AUTOSAR XML (schema 00044)
package /E40_Platform_System_SystemPackage/Components
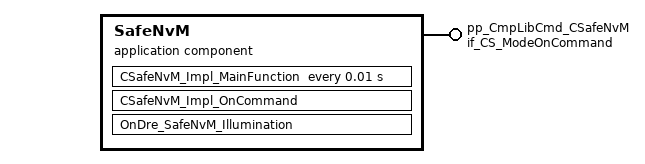
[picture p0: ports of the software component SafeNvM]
  application sw component type SafeNvM
    provide port pp_CmpLibCmd_CSafeNvM: server-com-spec{operation=Impl_OnCommand, queue-length=1}, provided-interface=if_CS_ModeOnCommand
    11 x provide/require port, all with nv-provide-com-spec=Value, nv-require-com-spec=Value:
      BsConst_Derating_Backlight_Disable: provided-required-interface=BsConst_Derating_Backlight_Disable
      BsConst_Temperature_Sensor_Conv: provided-required-interface=BsConst_Temperature_Sensor_Conv
      BsConst_Lookup_Curve_HotSpot_Coef_X: provided-required-interface=BsConst_Lookup_Curve_HotSpot_Coef_X
      BsConst_Display_Illum_Max_Level_Safe: provided-required-interface=BsConst_Display_Illum_Max_Level
      BsConst_Temp_Threshold_Hysteresis_Derating: provided-required-interface=BsConst_Temp_Threshold_Hysteresis_Derating
      BsConst_PWM_boost_bypass_duty: provided-required-interface=BsConst_PWM_boost_bypass_duty
      BsConst_BsConst_Illumination_ReservedByte: provided-required-interface=BsConst_BsConst_Illumination_ReservedByte
      BsConst_Lookup_Curve_HotSpot_Coef_Y: provided-required-interface=BsConst_Lookup_Curve_HotSpot_Coef_Y
      BsConst_Compensation_Line_Shift_b: provided-required-interface=BsConst_Compensation_Line_Shift_b
      BsConst_PCB_Temperature_Sensor_Conv: provided-required-interface=BsConst_PCB_Temperature_Sensor_Conv
      BsConst_Compensation_Line_Slope_m: provided-required-interface=BsConst_Compensation_Line_Slope_m
    behavior IB_SafeNvM: port-api-option{enable-take-address=false, error-handling=NO-TRANSFORMER-ERROR-HANDLING, indirect-api=false, port=pp_CmpLibCmd_CSafeNvM}
      operation invoked event OIE_pp_CmpLibCmd_CSafeNvM_CSafeNvM_Impl_OnCommandTrigByImpl_OnCommand: start-on-event=CSafeNvM_Impl_OnCommand, operation=pp_CmpLibCmd_CSafeNvM.Impl_OnCommand
      timing event TECSafeNvM_Impl_MainFunction: start-on-event=CSafeNvM_Impl_MainFunction, period=0.01
      11 x data received event, all with start-on-event=OnDre_SafeNvM_Illumination:
        DRT_OnDre_SafeNvM_Illumination_BsConst_BsConst_Illumination_ReservedByte_Value: data=BsConst_BsConst_Illumination_ReservedByte.Value
        DRT_OnDre_SafeNvM_Illumination_BsConst_Compensation_Line_Shift_b_Value: data=BsConst_Compensation_Line_Shift_b.Value
        DRT_OnDre_SafeNvM_Illumination_BsConst_Compensation_Line_Slope_m_Value: data=BsConst_Compensation_Line_Slope_m.Value
        DRT_OnDre_SafeNvM_Illumination_BsConst_Derating_Backlight_Disable_Value: data=BsConst_Derating_Backlight_Disable.Value
        DRT_OnDre_SafeNvM_Illumination_BsConst_Display_Illum_Max_Level_Safe_Value: data=BsConst_Display_Illum_Max_Level_Safe.Value
        DRT_OnDre_SafeNvM_Illumination_BsConst_Lookup_Curve_HotSpot_Coef_X_Value: data=BsConst_Lookup_Curve_HotSpot_Coef_X.Value
        DRT_OnDre_SafeNvM_Illumination_BsConst_Lookup_Curve_HotSpot_Coef_Y_Value: data=BsConst_Lookup_Curve_HotSpot_Coef_Y.Value
        DRT_OnDre_SafeNvM_Illumination_BsConst_PCB_Temperature_Sensor_Conv_Value: data=BsConst_PCB_Temperature_Sensor_Conv.Value
        DRT_OnDre_SafeNvM_Illumination_BsConst_PWM_boost_bypass_duty_Value: data=BsConst_PWM_boost_bypass_duty.Value
        DRT_OnDre_SafeNvM_Illumination_BsConst_Temp_Threshold_Hysteresis_Derating_Value: data=BsConst_Temp_Threshold_Hysteresis_Derating.Value
        DRT_OnDre_SafeNvM_Illumination_BsConst_Temperature_Sensor_Conv_Value: data=BsConst_Temperature_Sensor_Conv.Value
      runnable CSafeNvM_Impl_OnCommand: can-be-invoked-concurrently=true
      runnable CSafeNvM_Impl_MainFunction: can-be-invoked-concurrently=true
      runnable OnDre_SafeNvM_Illumination
  swc implementation IMPL_SafeNvM: behavior=IB_SafeNvM
    code-descriptors:
      code Default: artifact-descriptors=autosar-engineering-object=category=SWSRC
